# N32G41x register map
Vendor: Nsingtech Ltd.; File version: 1.0
CPU: CM4 r0p1, little endian, no MPU, no FPU, 4 interrupt priority bits
Registers are 32-bit, read-write, reset 0x0 unless marked. A register's access mark holds for its fields unless they carry their own. Offsets are from the block's base; [hi:lo] are bit positions; {n}, {i} and the like mark numbered series.

## RCC — Reset and Clock Control
Base 0x40021000
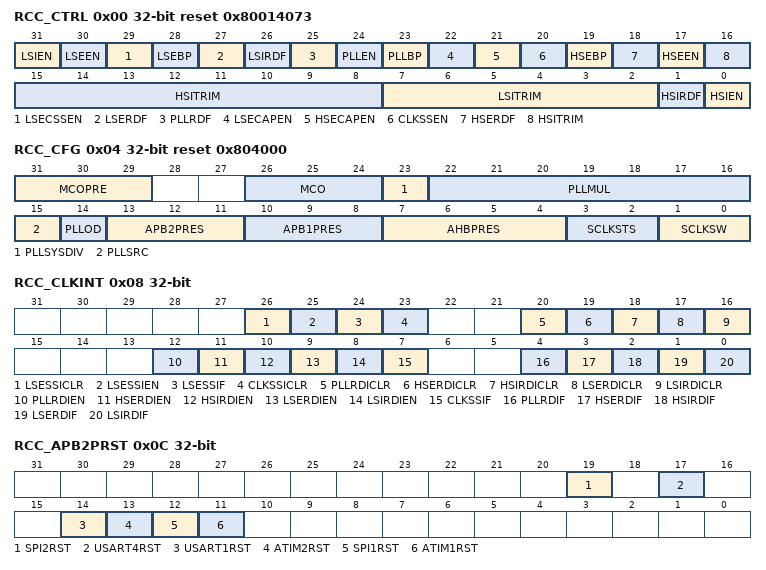
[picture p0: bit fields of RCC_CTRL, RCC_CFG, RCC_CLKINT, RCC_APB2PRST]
0x00 RCC_CTRL reset 0x80014073 — RCC Clock Control Register
  [31] LSIEN — LSI enable
  [30] LSEEN — LSE enable
  [29] LSECSSEN — LSE CSS enable
  [28] LSEBP — LSE bypass
  [27] LSERDF ro — LSE ready flag
  [26] LSIRDF ro — LSI ready flag
  [25] PLLRDF ro — PLL ready flag
  [24] PLLEN — PLL enable
  [23] PLLBP — PLL bypass mode
  [22] LSECAPEN — LSE capture enable
  [21] HSECAPEN — HSE capture enable
  [20] CLKSSEN — HSE CSS enable
  [19] HSEBP — HSE bypass
  [18] HSERDF ro — HSE ready flag
  [17] HSEEN — HSE enable
  [16:8] HSITRIM — HSI calibration
  [7:2] LSITRIM — LSI calibration
  [1] HSIRDF ro — HSI ready flag
  [0] HSIEN — HSI enable
0x04 RCC_CFG reset 0x804000 — RCC Clock Configuration Register
  [31:29] MCOPRE — MCO prescaler
  [26:24] MCO — MCU clock output source
  [23] PLLSYSDIV — PLL to system clock divider
  [22:16] PLLMUL — PLL multiplication factor
  [15] PLLSRC — PLL clock source
  [14] PLLOD — PLL output divider
  [13:11] APB2PRES — APB2 prescaler
  [10:8] APB1PRES — APB1 prescaler
  [7:4] AHBPRES — AHB prescaler
  [3:2] SCLKSTS ro — System clock status
  [1:0] SCLKSW — System clock switch
0x08 RCC_CLKINT — RCC Clock Interrupt Register
  [26] LSESSICLR wo — LSE CSS interrupt clear
  [25] LSESSIEN — LSE CSS int enable
  [24] LSESSIF ro — LSE CSS int flag
  [23] CLKSSICLR wo — HSE CSS int clear
  [20] PLLRDICLR wo — PLL ready int clear
  [19] HSERDICLR wo — HSE ready int clear
  [18] HSIRDICLR wo — HSI ready int clear
  [17] LSERDICLR wo — LSE ready int clear
  [16] LSIRDICLR wo — LSI ready int clear
  [12] PLLRDIEN — PLL ready int enable
  [11] HSERDIEN — HSE ready int enable
  [10] HSIRDIEN — HSI ready int enable
  [9] LSERDIEN — LSE ready int enable
  [8] LSIRDIEN — LSI ready int enable
  [7] CLKSSIF ro — HSE CSS int flag
  [4] PLLRDIF ro — PLL ready int flag
  [3] HSERDIF ro — HSE ready int flag
  [2] HSIRDIF ro — HSI ready int flag
  [1] LSERDIF ro — LSE ready int flag
  [0] LSIRDIF ro — LSI ready int flag
0x0C RCC_APB2PRST — RCC APB2 Peripheral Reset Register
  [19] SPI2RST — SPI2 reset
  [17] USART4RST — USART4 reset
  [14] USART1RST — USART1 reset
  [13] ATIM2RST — ATIM2 reset
  [12] SPI1RST — SPI1 reset
  [11] ATIM1RST — ATIM1 reset
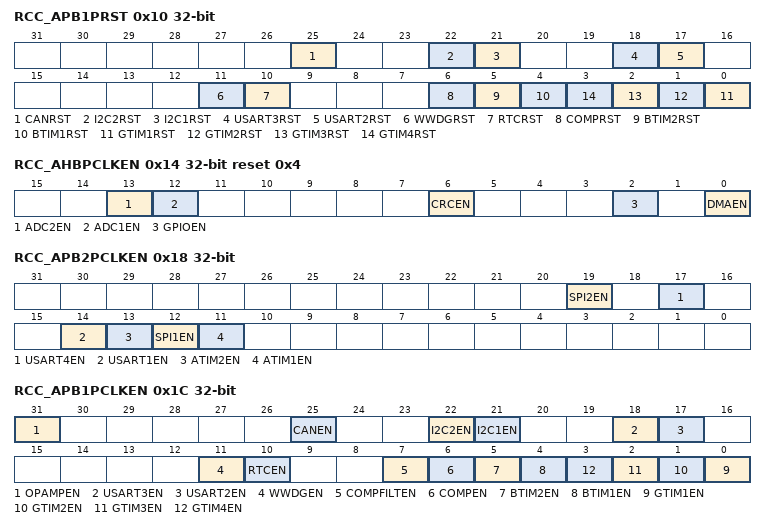
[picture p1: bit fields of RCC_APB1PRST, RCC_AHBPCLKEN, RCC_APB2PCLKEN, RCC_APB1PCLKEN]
0x10 RCC_APB1PRST — RCC APB1 Peripheral Reset Register
  [25] CANRST — CAN reset
  [22] I2C2RST — I2C2 reset
  [21] I2C1RST — I2C1 reset
  [18] USART3RST — USART3 reset
  [17] USART2RST — USART2 reset
  [11] WWDGRST — WWDG reset
  [10] RTCRST — RTC reset
  [6] COMPRST — COMP reset
  [5] BTIM2RST — BTIM2 reset
  [4] BTIM1RST — BTIM1 reset
  [n-1] GTIM{n}RST (n=1..4) — GTIM{n} reset
0x14 RCC_AHBPCLKEN reset 0x4 — RCC AHB Peripheral Clock Enable Register
  [13] ADC2EN — ADC2 clock enable
  [12] ADC1EN — ADC1 clock enable
  [6] CRCEN — CRC clock enable
  [2] GPIOEN — GPIO clock enable
  [0] DMAEN — DMA clock enable
0x18 RCC_APB2PCLKEN — RCC APB2 Peripheral Clock Enable Register
  [19] SPI2EN — SPI2 clock enable
  [17] USART4EN — USART4 clock enable
  [14] USART1EN — USART1 clock enable
  [13] ATIM2EN — ATIM2 clock enable
  [12] SPI1EN — SPI1 clock enable
  [11] ATIM1EN — ATIM1 clock enable
0x1C RCC_APB1PCLKEN — RCC APB1 Peripheral Clock Enable Register
  [31] OPAMPEN — OPAMP clock enable
  [25] CANEN — CAN clock enable
  [22] I2C2EN — I2C2 clock enable
  [21] I2C1EN — I2C1 clock enable
  [18] USART3EN — USART3 clock enable
  [17] USART2EN — USART2 clock enable
  [11] WWDGEN — WWDG clock enable
  [10] RTCEN — RTC clock enable
  [7] COMPFILTEN — COMP filter clock enable
  [6] COMPEN — COMP clock enable
  [5] BTIM2EN — BTIM2 clock enable
  [4] BTIM1EN — BTIM1 clock enable
  [n-1] GTIM{n}EN (n=1..4) — GTIM{n} clock enable
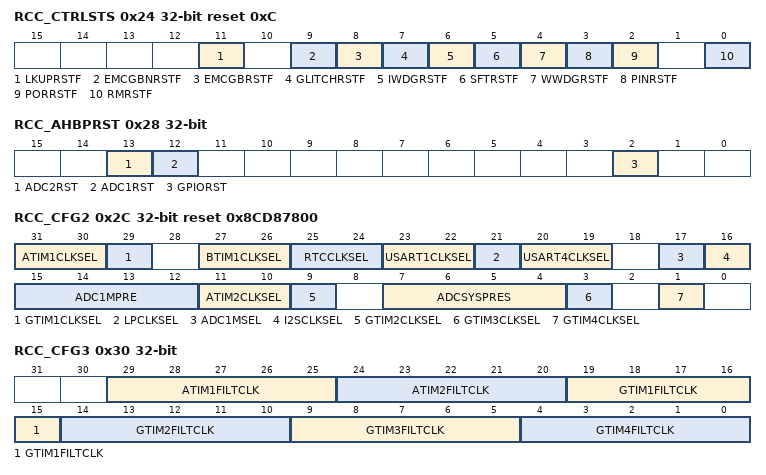
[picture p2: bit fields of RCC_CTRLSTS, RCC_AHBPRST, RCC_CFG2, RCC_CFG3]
0x24 RCC_CTRLSTS reset 0xC — RCC Control/Status Register
  [11] LKUPRSTF ro — CPU Lockup reset flag
  [9] EMCGBNRSTF ro — EMC GBN reset flag
  [8] EMCGBRSTF ro — EMC GB reset flag
  [7] GLITCHRSTF ro — GLITCH reset flag
  [6] IWDGRSTF ro — IWDG reset flag
  [5] SFTRSTF ro — Software reset flag
  [4] WWDGRSTF ro — WWDG reset flag
  [3] PINRSTF ro — NRST pin reset flag
  [2] PORRSTF ro — Power-on reset flag
  [0] RMRSTF — Clear reset flags
0x28 RCC_AHBPRST — RCC AHB Peripheral Reset Register
  [13] ADC2RST — ADC2 reset
  [12] ADC1RST — ADC1 reset
  [2] GPIORST — GPIO reset
0x2C RCC_CFG2 reset 0x8CD87800 — RCC Clock Configuration Register 2
  [31:30] ATIM1CLKSEL — ATIM1 clock source
  [29] GTIM1CLKSEL — GTIM1 clock source
  [27:26] BTIM1CLKSEL — BTIM1 clock source
  [25:24] RTCCLKSEL — RTC clock source
  [23:22] USART1CLKSEL — USART1 clock source
  [21] LPCLKSEL — Low power clock source
  [20:19] USART4CLKSEL — USART4 clock source
  [17] ADC1MSEL — ADC 1M clock source
  [16] I2SCLKSEL — I2S clock source
  [15:12] ADC1MPRE — ADC 1M prescaler
  [11:10] ATIM2CLKSEL — ATIM2 clock source
  [9] GTIM2CLKSEL — GTIM2 clock source
  [7:4] ADCSYSPRES — ADC SYSCLK prescaler
  [3] GTIM3CLKSEL — GTIM3 clock source
  [1] GTIM4CLKSEL — GTIM4 clock source
0x30 RCC_CFG3 — RCC Clock Configuration Register 3
  [29:25] ATIM1FILTCLK — ATIM1 filter clock divider
  [24:20] ATIM2FILTCLK — ATIM2 filter clock divider
  [24-5n:20-5n] GTIM{n}FILTCLK (n=1..4) — GTIM{n} filter clock divider
0x40 RCC_PLLCTRL — RCC PLL Clock Control Register
  [13:8] PLLINPRES — PLL input prescaler
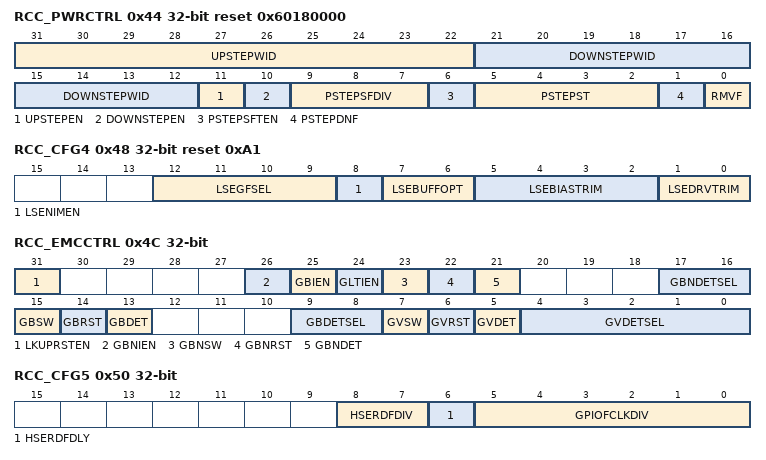
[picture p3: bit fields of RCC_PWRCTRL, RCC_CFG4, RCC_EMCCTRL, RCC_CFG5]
0x44 RCC_PWRCTRL reset 0x60180000 — RCC PWR Control Register
  [31:22] UPSTEPWID — Power up step width
  [21:12] DOWNSTEPWID — Power down step width
  [11] UPSTEPEN — Power up step enable
  [10] DOWNSTEPEN — Power down step enable
  [9:7] PSTEPSFDIV — SW power step divider
  [6] PSTEPSFTEN — SW power step enable
  [5:2] PSTEPST ro — PLL Power Step state
  [1] PSTEPDNF ro — PLL Power Step down flag
  [0] RMVF — Clear Power Step down flag
0x48 RCC_CFG4 reset 0xA1 — RCC Clock Configuration Register 4
  [12:9] LSEGFSEL — LSE glitch filter select
  [8] LSENIMEN — LSE anti-interference enable
  [7:6] LSEBUFFOPT — LSE buffer trimming
  [5:2] LSEBIASTRIM — LSE bias trimming
  [1:0] LSEDRVTRIM — LSE core trimming
0x4C RCC_EMCCTRL — RCC EMC Control Register
  [31] LKUPRSTEN — CPU Lockup reset enable
  [26] GBNIEN — EMC GBN int enable
  [25] GBIEN — EMC GB int enable
  [24] GLTIEN — GLITCH int enable
  [23] GBNSW — EMC GBN switch to LSI
  [22] GBNRST — EMC GBN reset
  [21] GBNDET — EMC GBN detect enable
  [17:16] GBNDETSEL — EMC GBN detect level
  [15] GBSW — EMC GB switch to LSI
  [14] GBRST — EMC GB reset
  [13] GBDET — EMC GB detect enable
  [9:8] GBDETSEL — EMC GB detect level
  [7] GVSW — GLITCH switch to LSI
  [6] GVRST — GLITCH reset
  [5] GVDET — GLITCH detect enable
  [4:0] GVDETSEL — GLITCH detect level
0x50 RCC_CFG5 — RCC Clock Configuration Register 5
  [8:7] HSERDFDIV — HSE ready delay divider
  [6] HSERDFDLY — HSE ready delay control
  [5:0] GPIOFCLKDIV — GPIO filter clock divider
